AUTOSAR XML (schema 00046)
package /ComponentTypes
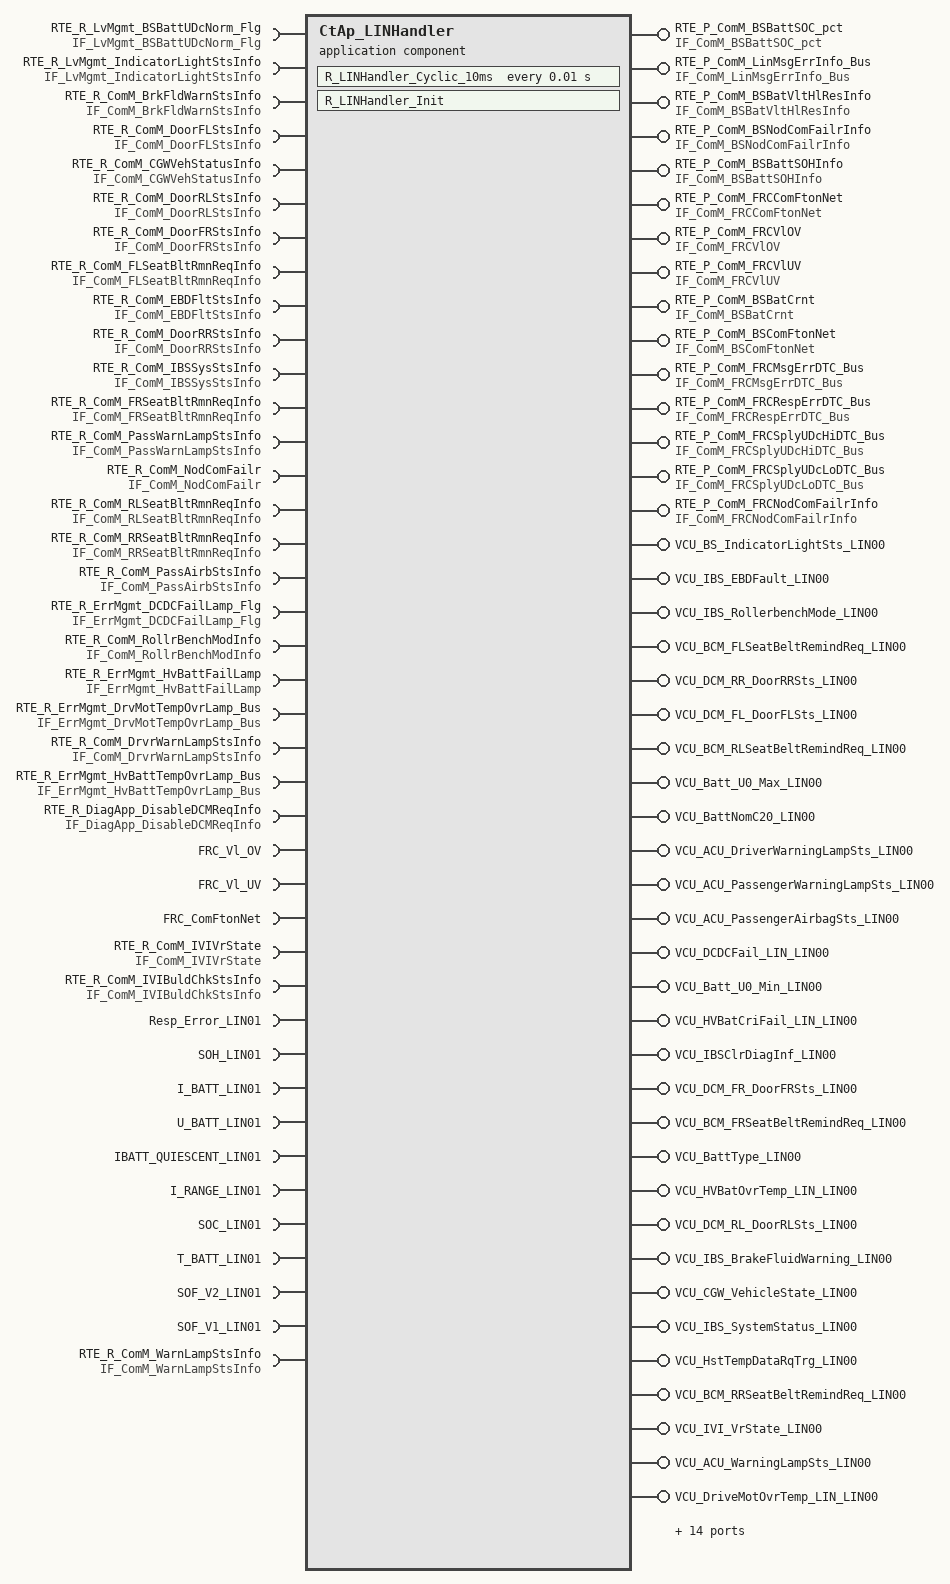
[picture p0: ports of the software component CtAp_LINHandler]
  application sw component type CtAp_LINHandler
    provide port RTE_P_ComM_BSBattSOC_pct: nonqueued-sender-com-spec{data-element=tec_ComM_BSBattSOC_pct, init-value=0}, provided-interface=IF_ComM_BSBattSOC_pct
    require port RTE_R_LvMgmt_BSBattUDcNorm_Flg: nonqueued-receiver-com-spec{data-element=tec_LvMgmt_BSBattUDcNorm_Flg, filter=data-filter-type=ALWAYS, init-value=0}, required-interface=IF_LvMgmt_BSBattUDcNorm_Flg
    4 x provide port:
      RTE_P_ComM_LinMsgErrInfo_Bus: nonqueued-sender-com-spec{data-element=tec_ComM_LinMsgErrInfo_Bus, init-value=fields=[ComM_MonStatLinMsgTimeoutDTCInfo:0, ComM_MonResLinMsgTimeoutDTCInfo:0, ComM_ErrStatLinMsgTimeoutDTCInfo:0, ComM_ErrRestatLinMsgTimeoutDTCInfo:0]}, provided-interface=IF_ComM_LinMsgErrInfo_Bus
      RTE_P_ComM_BSBatVltHlResInfo: nonqueued-sender-com-spec{data-element=tec_ComM_BSBatVltHlResInfo, init-value=0}, provided-interface=IF_ComM_BSBatVltHlResInfo
      RTE_P_ComM_BSNodComFailrInfo: nonqueued-sender-com-spec{data-element=tec_ComM_BSNodComFailrInfo, init-value=0}, provided-interface=IF_ComM_BSNodComFailrInfo
      RTE_P_ComM_BSBattSOHInfo: nonqueued-sender-com-spec{data-element=tec_ComM_BSBattSOHInfo, init-value=0}, provided-interface=IF_ComM_BSBattSOHInfo
    26 x require port:
      RTE_R_LvMgmt_IndicatorLightStsInfo: nonqueued-receiver-com-spec{data-element=tec_LvMgmt_IndicatorLightStsInfo, filter=data-filter-type=ALWAYS, init-value=0}, required-interface=IF_LvMgmt_IndicatorLightStsInfo
      RTE_R_ComM_BrkFldWarnStsInfo: nonqueued-receiver-com-spec{data-element=tec_ComM_BrkFldWarnStsInfo, filter=data-filter-type=ALWAYS, init-value=0}, required-interface=IF_ComM_BrkFldWarnStsInfo
      RTE_R_ComM_DoorFLStsInfo: nonqueued-receiver-com-spec{data-element=tec_ComM_DoorFLStsInfo, filter=data-filter-type=ALWAYS, init-value=0}, required-interface=IF_ComM_DoorFLStsInfo
      RTE_R_ComM_CGWVehStatusInfo: nonqueued-receiver-com-spec{data-element=tec_ComM_CGWVehStatusInfo, filter=data-filter-type=ALWAYS, init-value=0}, required-interface=IF_ComM_CGWVehStatusInfo
      RTE_R_ComM_DoorRLStsInfo: nonqueued-receiver-com-spec{data-element=tec_ComM_DoorRLStsInfo, filter=data-filter-type=ALWAYS, init-value=0}, required-interface=IF_ComM_DoorRLStsInfo
      RTE_R_ComM_DoorFRStsInfo: nonqueued-receiver-com-spec{data-element=tec_ComM_DoorFRStsInfo, filter=data-filter-type=ALWAYS, init-value=0}, required-interface=IF_ComM_DoorFRStsInfo
      RTE_R_ComM_FLSeatBltRmnReqInfo: nonqueued-receiver-com-spec{data-element=tec_ComM_FLSeatBltRmnReqInfo, filter=data-filter-type=ALWAYS, init-value=0}, required-interface=IF_ComM_FLSeatBltRmnReqInfo
      RTE_R_ComM_EBDFltStsInfo: nonqueued-receiver-com-spec{data-element=tec_ComM_EBDFltStsInfo, filter=data-filter-type=ALWAYS, init-value=0}, required-interface=IF_ComM_EBDFltStsInfo
      RTE_R_ComM_DoorRRStsInfo: nonqueued-receiver-com-spec{data-element=tec_ComM_DoorRRStsInfo, filter=data-filter-type=ALWAYS, init-value=0}, required-interface=IF_ComM_DoorRRStsInfo
      RTE_R_ComM_IBSSysStsInfo: nonqueued-receiver-com-spec{data-element=tec_ComM_IBSSysStsInfo, filter=data-filter-type=ALWAYS, init-value=0}, required-interface=IF_ComM_IBSSysStsInfo
      RTE_R_ComM_FRSeatBltRmnReqInfo: nonqueued-receiver-com-spec{data-element=tec_ComM_FRSeatBltRmnReqInfo, filter=data-filter-type=ALWAYS, init-value=0}, required-interface=IF_ComM_FRSeatBltRmnReqInfo
      RTE_R_ComM_PassWarnLampStsInfo: nonqueued-receiver-com-spec{data-element=tec_ComM_PassWarnLampStsInfo, filter=data-filter-type=ALWAYS, init-value=0}, required-interface=IF_ComM_PassWarnLampStsInfo
      RTE_R_ComM_NodComFailr: required-interface=IF_ComM_NodComFailr
        required-com-specs:
          data-element=tec_ComM_APTCNodComFailr_Flg, filter=data-filter-type=ALWAYS, init-value=0
          data-element=tec_ComM_ADCUNodComFailr_Flg, filter=data-filter-type=ALWAYS, init-value=0
          data-element=tec_ComM_ACUNodComFailr_Flg, filter=data-filter-type=ALWAYS, init-value=0
          data-element=tec_ComM_SGWNodComFailr_Flg, filter=data-filter-type=ALWAYS, init-value=0
          data-element=tec_ComM_CGWNodComFailr_Flg, filter=data-filter-type=ALWAYS, init-value=0
          data-element=tec_ComM_TCUNodComFailr_Flg, filter=data-filter-type=ALWAYS, init-value=0
          data-element=tec_ComM_BCMNodComFailr_Flg, filter=data-filter-type=ALWAYS, init-value=0
          data-element=tec_ComM_PRNDNodComFailr_Flg, filter=data-filter-type=ALWAYS, init-value=0
          data-element=tec_ComM_IVINodComFailr_Flg, filter=data-filter-type=ALWAYS, init-value=0
          data-element=tec_ComM_DCDCNodComFailr_Flg, filter=data-filter-type=ALWAYS, init-value=0
          data-element=tec_ComM_OBCNodComFailr_Flg, filter=data-filter-type=ALWAYS, init-value=0
          data-element=tec_ComM_CHIBSNodComFailr_Flg, filter=data-filter-type=ALWAYS, init-value=0
          data-element=tec_ComM_MCUNodComFailr_Flg, filter=data-filter-type=ALWAYS, init-value=0
          data-element=tec_ComM_EVCOMNodComFailr_Flg, filter=data-filter-type=ALWAYS, init-value=0
          data-element=tec_ComM_EPTIBSNodComFailr_Flg, filter=data-filter-type=ALWAYS, init-value=0
          data-element=tec_ComM_DCMNodComFailr_Flg, filter=data-filter-type=ALWAYS, init-value=0
          data-element=tec_ComM_BMSNodComFailr_Flg, filter=data-filter-type=ALWAYS, init-value=0
          data-element=tec_ComM_DCMRRNodComFailr_Flg, filter=data-filter-type=ALWAYS, init-value=0
          data-element=tec_ComM_DCMRLNodComFailr_Flg, filter=data-filter-type=ALWAYS, init-value=0
          data-element=tec_ComM_DCMFRNodComFailr_Flg, filter=data-filter-type=ALWAYS, init-value=0
          data-element=tec_ComM_DCMFLNodComFailr_Flg, filter=data-filter-type=ALWAYS, init-value=0
          data-element=tec_ComM_SGWCHNodComFailr_Flg, filter=data-filter-type=ALWAYS, init-value=0
      RTE_R_ComM_RLSeatBltRmnReqInfo: nonqueued-receiver-com-spec{data-element=tec_ComM_RLSeatBltRmnReqInfo, filter=data-filter-type=ALWAYS, init-value=0}, required-interface=IF_ComM_RLSeatBltRmnReqInfo
      RTE_R_ComM_RRSeatBltRmnReqInfo: nonqueued-receiver-com-spec{data-element=tec_ComM_RRSeatBltRmnReqInfo, filter=data-filter-type=ALWAYS, init-value=0}, required-interface=IF_ComM_RRSeatBltRmnReqInfo
      RTE_R_ComM_PassAirbStsInfo: nonqueued-receiver-com-spec{data-element=tec_ComM_PassAirbStsInfo, filter=data-filter-type=ALWAYS, init-value=0}, required-interface=IF_ComM_PassAirbStsInfo
      RTE_R_ErrMgmt_DCDCFailLamp_Flg: nonqueued-receiver-com-spec{data-element=tec_ErrMgmt_DCDCFailLamp_Flg, filter=data-filter-type=ALWAYS, init-value=0}, required-interface=IF_ErrMgmt_DCDCFailLamp_Flg
      RTE_R_ComM_RollrBenchModInfo: nonqueued-receiver-com-spec{data-element=tec_ComM_RollrBenchModInfo, filter=data-filter-type=ALWAYS, init-value=0}, required-interface=IF_ComM_RollrBenchModInfo
      RTE_R_ErrMgmt_HvBattFailLamp: nonqueued-receiver-com-spec{data-element=tec_ErrMgmt_HvBattFailLamp, filter=data-filter-type=ALWAYS, init-value=0}, required-interface=IF_ErrMgmt_HvBattFailLamp
      RTE_R_ErrMgmt_DrvMotTempOvrLamp_Bus: nonqueued-receiver-com-spec{data-element=tec_ErrMgmt_DrvMotTempOvrLamp_Bus, filter=data-filter-type=ALWAYS, init-value=fields=[ErrMgmt_MonStatMCUTempOvr:0, ErrMgmt_MonResMCUTempOvr:0, ErrMgmt_ErrStatMCUTempOvr:0, ErrMgmt_ErrResMCUTempOvr:0]}, required-interface=IF_ErrMgmt_DrvMotTempOvrLamp_Bus
      RTE_R_ComM_DrvrWarnLampStsInfo: nonqueued-receiver-com-spec{data-element=tec_ComM_DrvrWarnLampStsInfo, filter=data-filter-type=ALWAYS, init-value=0}, required-interface=IF_ComM_DrvrWarnLampStsInfo
      RTE_R_ErrMgmt_HvBattTempOvrLamp_Bus: nonqueued-receiver-com-spec{data-element=tec_ErrMgmt_HvBattTempOvrLamp_Bus, filter=data-filter-type=ALWAYS, init-value=fields=[ErrMgmt_MonStatBMSTempOvr:0, ErrMgmt_MonResBMSTempOvr:0, ErrMgmt_ErrStatBMSTempOvr:0, ErrMgmt_ErrResBMSTempOvr:0]}, required-interface=IF_ErrMgmt_HvBattTempOvrLamp_Bus
      RTE_R_DiagApp_DisableDCMReqInfo: nonqueued-receiver-com-spec{data-element=tec_DiagApp_DisableDCMReqInfo, filter=data-filter-type=ALWAYS, init-value=0}, required-interface=IF_DiagApp_DisableDCMReqInfo
      FRC_Vl_OV: nonqueued-receiver-com-spec{data-element=FRC_Vl_OV, init-value=1}, required-interface=FRC_Vl_OV
      FRC_Vl_UV: nonqueued-receiver-com-spec{data-element=FRC_Vl_UV, init-value=1}, required-interface=FRC_Vl_UV
      FRC_ComFtonNet: nonqueued-receiver-com-spec{data-element=FRC_ComFtonNet, enable-update=true, init-value=1}, required-interface=FRC_ComFtonNet
    5 x provide port:
      RTE_P_ComM_FRCComFtonNet: nonqueued-sender-com-spec{data-element=tec_ComM_FRCComFtonNet, init-value=0}, provided-interface=IF_ComM_FRCComFtonNet
      RTE_P_ComM_FRCVlOV: nonqueued-sender-com-spec{data-element=tec_ComM_FRCVlOV, init-value=0}, provided-interface=IF_ComM_FRCVlOV
      RTE_P_ComM_FRCVlUV: nonqueued-sender-com-spec{data-element=tec_ComM_FRCVlUV, init-value=0}, provided-interface=IF_ComM_FRCVlUV
      RTE_P_ComM_BSBatCrnt: nonqueued-sender-com-spec{data-element=tec_ComM_BSBatCrnt, init-value=0}, provided-interface=IF_ComM_BSBatCrnt
      RTE_P_ComM_BSComFtonNet: nonqueued-sender-com-spec{data-element=tec_ComM_BSComFtonNet, init-value=0}, provided-interface=IF_ComM_BSComFtonNet
    require port RTE_R_ComM_IVIVrState: nonqueued-receiver-com-spec{data-element=tec_ComM_IVIVrState, filter=data-filter-type=ALWAYS, init-value=0}, required-interface=IF_ComM_IVIVrState
    34 x provide port:
      RTE_P_ComM_FRCMsgErrDTC_Bus: nonqueued-sender-com-spec=tec_ComM_FRCMsgErrDTC_Bus, provided-interface=IF_ComM_FRCMsgErrDTC_Bus
      RTE_P_ComM_FRCRespErrDTC_Bus: nonqueued-sender-com-spec{data-element=tec_ComM_FRCRespErrDTC_Bus, init-value=fields=[ComM_MonStatLinFRCRespErrDTC:0, ComM_MonResLinFRCRespErrDTC:0, ComM_ErrStatFRCRespErrDTC:0, ComM_ErrResFRCRespErrDTC:0]}, provided-interface=IF_ComM_FRCRespErrDTC_Bus
      RTE_P_ComM_FRCSplyUDcHiDTC_Bus: nonqueued-sender-com-spec{data-element=tec_ComM_FRCSplyUDcHiDTC_Bus, init-value=fields=[ComM_MonStatFRCSplyUDcHiDTC:0, ComM_MonResFRCSplyUDcHiDTC:0, ComM_ErrStatFRCSplyUDcHiDTC:0, ComM_ErrResFRCSplyUDcHiDTC:0]}, provided-interface=IF_ComM_FRCSplyUDcHiDTC_Bus
      RTE_P_ComM_FRCSplyUDcLoDTC_Bus: nonqueued-sender-com-spec{data-element=tec_ComM_FRCSplyUDcLoDTC_Bus, init-value=fields=[ComM_MonStatFRCSplyUDcLoDTC:0, ComM_MonResFRCSplyUDcLoDTC:0, ComM_ErrStatFRCSplyUDcLoDTC:0, ComM_ErrResFRCSplyUDcLoDTC:0]}, provided-interface=IF_ComM_FRCSplyUDcLoDTC_Bus
      RTE_P_ComM_FRCNodComFailrInfo: nonqueued-sender-com-spec{data-element=tec_ComM_FRCNodComFailrInfo, init-value=0}, provided-interface=IF_ComM_FRCNodComFailrInfo
      VCU_BS_IndicatorLightSts_LIN00: nonqueued-sender-com-spec{data-element=VCU_BS_IndicatorLightSts_LIN, init-value=0}, provided-interface=VCU_BS_IndicatorLightSts_LIN00
      VCU_IBS_EBDFault_LIN00: nonqueued-sender-com-spec{data-element=VCU_IBS_EBDFault_LIN, init-value=0}, provided-interface=VCU_IBS_EBDFault_LIN00
      VCU_IBS_RollerbenchMode_LIN00: nonqueued-sender-com-spec{data-element=VCU_IBS_RollerbenchMode_LIN, init-value=0}, provided-interface=VCU_IBS_RollerbenchMode_LIN00
      VCU_BCM_FLSeatBeltRemindReq_LIN00: nonqueued-sender-com-spec{data-element=VCU_BCM_FLSeatBeltRemindReq_LIN, init-value=0}, provided-interface=VCU_BCM_FLSeatBeltRemindReq_LIN00
      VCU_DCM_RR_DoorRRSts_LIN00: nonqueued-sender-com-spec{data-element=VCU_DCM_RR_DoorRRSts_LIN, init-value=0}, provided-interface=VCU_DCM_RR_DoorRRSts_LIN00
      VCU_DCM_FL_DoorFLSts_LIN00: nonqueued-sender-com-spec{data-element=VCU_DCM_FL_DoorFLSts_LIN, init-value=0}, provided-interface=VCU_DCM_FL_DoorFLSts_LIN00
      VCU_BCM_RLSeatBeltRemindReq_LIN00: nonqueued-sender-com-spec{data-element=VCU_BCM_RLSeatBeltRemindReq_LIN, init-value=0}, provided-interface=VCU_BCM_RLSeatBeltRemindReq_LIN00
      VCU_Batt_U0_Max_LIN00: nonqueued-sender-com-spec{data-element=VCU_Batt_U0_Max_LIN, init-value=2}, provided-interface=VCU_Batt_U0_Max_LIN00
      VCU_BattNomC20_LIN00: nonqueued-sender-com-spec{data-element=VCU_BattNomC20_LIN, init-value=70}, provided-interface=VCU_BattNomC20_LIN00
      VCU_ACU_DriverWarningLampSts_LIN00: nonqueued-sender-com-spec{data-element=VCU_ACU_DriverWarningLampSts_LIN, init-value=0}, provided-interface=VCU_ACU_DriverWarningLampSts_LIN00
      VCU_ACU_PassengerWarningLampSts_LIN00: nonqueued-sender-com-spec{data-element=VCU_ACU_PassengerWarningLampSts_LIN, init-value=0}, provided-interface=VCU_ACU_PassengerWarningLampSts_LIN00
      VCU_ACU_PassengerAirbagSts_LIN00: nonqueued-sender-com-spec{data-element=VCU_ACU_PassengerAirbagSts_LIN, init-value=0}, provided-interface=VCU_ACU_PassengerAirbagSts_LIN00
      VCU_DCDCFail_LIN_LIN00: nonqueued-sender-com-spec{data-element=VCU_DCDCFail_LIN_LIN, init-value=0}, provided-interface=VCU_DCDCFail_LIN_LIN00
      VCU_Batt_U0_Min_LIN00: nonqueued-sender-com-spec{data-element=VCU_Batt_U0_Min_LIN, init-value=2}, provided-interface=VCU_Batt_U0_Min_LIN00
      VCU_HVBatCriFail_LIN_LIN00: nonqueued-sender-com-spec{data-element=VCU_HVBatCriFail_LIN_LIN, init-value=0}, provided-interface=VCU_HVBatCriFail_LIN_LIN00
      VCU_IBSClrDiagInf_LIN00: nonqueued-sender-com-spec{data-element=VCU_IBSClrDiagInf_LIN, init-value=0}, provided-interface=VCU_IBSClrDiagInf_LIN00
      VCU_DCM_FR_DoorFRSts_LIN00: nonqueued-sender-com-spec{data-element=VCU_DCM_FR_DoorFRSts_LIN, init-value=0}, provided-interface=VCU_DCM_FR_DoorFRSts_LIN00
      VCU_BCM_FRSeatBeltRemindReq_LIN00: nonqueued-sender-com-spec{data-element=VCU_BCM_FRSeatBeltRemindReq_LIN, init-value=0}, provided-interface=VCU_BCM_FRSeatBeltRemindReq_LIN00
      VCU_BattType_LIN00: nonqueued-sender-com-spec{data-element=VCU_BattType_LIN, init-value=0}, provided-interface=VCU_BattType_LIN00
      VCU_HVBatOvrTemp_LIN_LIN00: nonqueued-sender-com-spec{data-element=VCU_HVBatOvrTemp_LIN_LIN, init-value=0}, provided-interface=VCU_HVBatOvrTemp_LIN_LIN00
      VCU_DCM_RL_DoorRLSts_LIN00: nonqueued-sender-com-spec{data-element=VCU_DCM_RL_DoorRLSts_LIN, init-value=0}, provided-interface=VCU_DCM_RL_DoorRLSts_LIN00
      VCU_IBS_BrakeFluidWarning_LIN00: nonqueued-sender-com-spec{data-element=VCU_IBS_BrakeFluidWarning_LIN, init-value=0}, provided-interface=VCU_IBS_BrakeFluidWarning_LIN00
      VCU_CGW_VehicleState_LIN00: nonqueued-sender-com-spec{data-element=VCU_CGW_VehicleState_LIN, init-value=0}, provided-interface=VCU_CGW_VehicleState_LIN00
      VCU_IBS_SystemStatus_LIN00: nonqueued-sender-com-spec{data-element=VCU_IBS_SystemStatus_LIN, init-value=0}, provided-interface=VCU_IBS_SystemStatus_LIN00
      VCU_HstTempDataRqTrg_LIN00: nonqueued-sender-com-spec{data-element=VCU_HstTempDataRqTrg_LIN, init-value=0}, provided-interface=VCU_HstTempDataRqTrg_LIN00
      VCU_BCM_RRSeatBeltRemindReq_LIN00: nonqueued-sender-com-spec{data-element=VCU_BCM_RRSeatBeltRemindReq_LIN, init-value=0}, provided-interface=VCU_BCM_RRSeatBeltRemindReq_LIN00
      VCU_IVI_VrState_LIN00: nonqueued-sender-com-spec{data-element=VCU_IVI_VrState_LIN, init-value=0}, provided-interface=VCU_IVI_VrState_LIN00
      VCU_ACU_WarningLampSts_LIN00: nonqueued-sender-com-spec{data-element=VCU_ACU_WarningLampSts_LIN, init-value=0}, provided-interface=VCU_ACU_WarningLampSts_LIN00
      VCU_DriveMotOvrTemp_LIN_LIN00: nonqueued-sender-com-spec{data-element=VCU_DriveMotOvrTemp_LIN_LIN, init-value=0}, provided-interface=VCU_DriveMotOvrTemp_LIN_LIN00
    require port RTE_R_ComM_IVIBuldChkStsInfo: nonqueued-receiver-com-spec{data-element=tec_ComM_IVIBuldChkStsInfo, filter=data-filter-type=ALWAYS, init-value=0}, required-interface=IF_ComM_IVIBuldChkStsInfo
    provide port VCU_IVI_BulbCheckStsLIN01: nonqueued-sender-com-spec{data-element=VCU_IVI_BulbCheckStsLIN01, init-value=0}, provided-interface=VCU_IVI_BulbCheckStsLIN01
    provide port RTE_P_ComM_BSHCrnt: nonqueued-sender-com-spec{data-element=tec_ComM_BSHCrnt, init-value=0}, provided-interface=IF_ComM_BSHCrnt
    provide port RTE_P_ComM_BSQuiescentCurrent: nonqueued-sender-com-spec{data-element=tec_ComM_BSQuiescentCurrent, init-value=0}, provided-interface=IF_ComM_BSQuiescentCurrent
    require port Resp_Error_LIN01: nonqueued-receiver-com-spec{data-element=Resp_Error_LIN01, enable-update=true, init-value=0}, required-interface=Resp_Error_LIN01
    provide port RTE_P_ComM_BSBattIDcInfo: nonqueued-sender-com-spec{data-element=tec_ComM_BSBattIDcInfo, init-value=0}, provided-interface=IF_ComM_BSBattIDcInfo
    provide port RTE_P_ComM_BSBattTempInfo: nonqueued-sender-com-spec=tec_ComM_BSBattTempInfo, provided-interface=IF_ComM_BSBattTempInfo
    7 x require port:
      SOH_LIN01: nonqueued-receiver-com-spec{data-element=SOH_LIN01, init-value=255}, required-interface=SOH_LIN01
      I_BATT_LIN01: nonqueued-receiver-com-spec{data-element=I_BATT_LIN01, init-value=65535}, required-interface=I_BATT_LIN01
      U_BATT_LIN01: nonqueued-receiver-com-spec{data-element=U_BATT_LIN01, init-value=16383}, required-interface=U_BATT_LIN01
      IBATT_QUIESCENT_LIN01: nonqueued-receiver-com-spec{data-element=IBATT_QUIESCENT_LIN01, init-value=255}, required-interface=IBATT_QUIESCENT_LIN01
      I_RANGE_LIN01: nonqueued-receiver-com-spec{data-element=I_RANGE_LIN01, init-value=3}, required-interface=I_RANGE_LIN01
      SOC_LIN01: nonqueued-receiver-com-spec{data-element=SOC_LIN01, init-value=1}, required-interface=SOC_LIN01
      T_BATT_LIN01: nonqueued-receiver-com-spec{data-element=T_BATT_LIN01, init-value=255}, required-interface=T_BATT_LIN01
    7 x provide port:
      ChargeCurrWU_Ena_LIN01: nonqueued-sender-com-spec{data-element=ChargeCurrWU_Ena_LIN01, init-value=1}, provided-interface=ChargeCurrWU_Ena_LIN01
      SOCWU_Ena_LIN01: nonqueued-sender-com-spec{data-element=SOCWU_Ena_LIN01, init-value=1}, provided-interface=SOCWU_Ena_LIN01
      DisChargeCurrWU_Treshold_LIN01: nonqueued-sender-com-spec{data-element=DisChargeCurrWU_Treshold_LIN01, init-value=145}, provided-interface=DisChargeCurrWU_Treshold_LIN01
      SOCWU_Treshold_LIN01: nonqueued-sender-com-spec{data-element=SOCWU_Treshold_LIN01, init-value=70}, provided-interface=SOCWU_Treshold_LIN01
      DisChargeCurrWU_Ena_LIN01: nonqueued-sender-com-spec{data-element=DisChargeCurrWU_Ena_LIN01, init-value=1}, provided-interface=DisChargeCurrWU_Ena_LIN01
      ChargeCurrWU_Treshold_LIN01: nonqueued-sender-com-spec{data-element=ChargeCurrWU_Treshold_LIN01, init-value=30}, provided-interface=ChargeCurrWU_Treshold_LIN01
      RTE_P_ComM_BS01_IsUpdated: nonqueued-sender-com-spec{data-element=tec_ComM_BS01_IsUpdated, init-value=0}, provided-interface=IF_ComM_BS01_IsUpdated
    require port SOF_V2_LIN01: nonqueued-receiver-com-spec{data-element=SOF_V2_LIN01, init-value=255}, required-interface=SOF_V2_LIN01
    require port SOF_V1_LIN01: nonqueued-receiver-com-spec{data-element=SOF_V1_LIN01, init-value=255}, required-interface=SOF_V1_LIN01
    provide port RTE_P_ComM_BSSOFV1Info: nonqueued-sender-com-spec{data-element=tec_ComM_BSSOFV1Info, init-value=0}, provided-interface=IF_ComM_BSSOFV1Info
    provide port RTE_P_ComM_BSSOFV2Info: nonqueued-sender-com-spec{data-element=tec_ComM_BSSOFV2Info, init-value=0}, provided-interface=IF_ComM_BSSOFV2Info
    require port RTE_R_ComM_WarnLampStsInfo: nonqueued-receiver-com-spec{data-element=tec_ComM_WarnLampStsInfo, filter=data-filter-type=ALWAYS, init-value=0}, required-interface=IF_ComM_WarnLampStsInfo
    behavior CtAp_LINHandler_InternalBehavior
      timing event TMT_R_LINHandler_Cyclic_10ms: start-on-event=R_LINHandler_Cyclic_10ms, period=0.01
      init event CtAp_LinHandler_InitEvent: start-on-event=R_LINHandler_Init
      runnable R_LINHandler_Cyclic_10ms
        data-receive-point-by-arguments:
          48 x access:
            REC_FRC_ComFtonNet_FRC_ComFtonNet: accessed-variable=FRC_ComFtonNet.FRC_ComFtonNet
            REC_FRC_Vl_OV_FRC_Vl_OV: accessed-variable=FRC_Vl_OV.FRC_Vl_OV
            REC_FRC_Vl_UV_FRC_Vl_UV: accessed-variable=FRC_Vl_UV.FRC_Vl_UV
            REC_RTE_R_ComM_BrkFldWarnStsInfo_tec_ComM_BrkFldWarnStsInfo: accessed-variable=RTE_R_ComM_BrkFldWarnStsInfo.tec_ComM_BrkFldWarnStsInfo
            REC_RTE_R_ComM_CGWVehStatusInfo_tec_ComM_CGWVehStatusInfo: accessed-variable=RTE_R_ComM_CGWVehStatusInfo.tec_ComM_CGWVehStatusInfo
            REC_RTE_R_ComM_DoorFLStsInfo_tec_ComM_DoorFLStsInfo: accessed-variable=RTE_R_ComM_DoorFLStsInfo.tec_ComM_DoorFLStsInfo
            REC_RTE_R_ComM_DoorFRStsInfo_tec_ComM_DoorFRStsInfo: accessed-variable=RTE_R_ComM_DoorFRStsInfo.tec_ComM_DoorFRStsInfo
            REC_RTE_R_ComM_DoorRLStsInfo_tec_ComM_DoorRLStsInfo: accessed-variable=RTE_R_ComM_DoorRLStsInfo.tec_ComM_DoorRLStsInfo
            REC_RTE_R_ComM_DoorRRStsInfo_tec_ComM_DoorRRStsInfo: accessed-variable=RTE_R_ComM_DoorRRStsInfo.tec_ComM_DoorRRStsInfo
            REC_RTE_R_ComM_DrvrWarnLampStsInfo_tec_ComM_DrvrWarnLampStsInfo: accessed-variable=RTE_R_ComM_DrvrWarnLampStsInfo.tec_ComM_DrvrWarnLampStsInfo
            REC_RTE_R_ComM_EBDFltStsInfo_tec_ComM_EBDFltStsInfo: accessed-variable=RTE_R_ComM_EBDFltStsInfo.tec_ComM_EBDFltStsInfo
            REC_RTE_R_ComM_FLSeatBltRmnReqInfo_tec_ComM_FLSeatBltRmnReqInfo: accessed-variable=RTE_R_ComM_FLSeatBltRmnReqInfo.tec_ComM_FLSeatBltRmnReqInfo
            REC_RTE_R_ComM_FRSeatBltRmnReqInfo_tec_ComM_FRSeatBltRmnReqInfo: accessed-variable=RTE_R_ComM_FRSeatBltRmnReqInfo.tec_ComM_FRSeatBltRmnReqInfo
            REC_RTE_R_ComM_IBSSysStsInfo_tec_ComM_IBSSysStsInfo: accessed-variable=RTE_R_ComM_IBSSysStsInfo.tec_ComM_IBSSysStsInfo
            REC_RTE_R_ComM_IVIVrState_tec_ComM_IVIVrState: accessed-variable=RTE_R_ComM_IVIVrState.tec_ComM_IVIVrState
            REC_RTE_R_ComM_NodComFailr_tec_ComM_ACUNodComFailr_Flg: accessed-variable=RTE_R_ComM_NodComFailr.tec_ComM_ACUNodComFailr_Flg
            REC_RTE_R_ComM_NodComFailr_tec_ComM_BCMNodComFailr_Flg: accessed-variable=RTE_R_ComM_NodComFailr.tec_ComM_BCMNodComFailr_Flg
            REC_RTE_R_ComM_NodComFailr_tec_ComM_CGWNodComFailr_Flg: accessed-variable=RTE_R_ComM_NodComFailr.tec_ComM_CGWNodComFailr_Flg
            REC_RTE_R_ComM_NodComFailr_tec_ComM_CHIBSNodComFailr_Flg: accessed-variable=RTE_R_ComM_NodComFailr.tec_ComM_CHIBSNodComFailr_Flg
            REC_RTE_R_ComM_NodComFailr_tec_ComM_DCMFLNodComFailr_Flg: accessed-variable=RTE_R_ComM_NodComFailr.tec_ComM_DCMFLNodComFailr_Flg
            REC_RTE_R_ComM_NodComFailr_tec_ComM_DCMFRNodComFailr_Flg: accessed-variable=RTE_R_ComM_NodComFailr.tec_ComM_DCMFRNodComFailr_Flg
            REC_RTE_R_ComM_NodComFailr_tec_ComM_DCMRLNodComFailr_Flg: accessed-variable=RTE_R_ComM_NodComFailr.tec_ComM_DCMRLNodComFailr_Flg
            REC_RTE_R_ComM_NodComFailr_tec_ComM_DCMRRNodComFailr_Flg: accessed-variable=RTE_R_ComM_NodComFailr.tec_ComM_DCMRRNodComFailr_Flg
            REC_RTE_R_ComM_NodComFailr_tec_ComM_IVINodComFailr_Flg: accessed-variable=RTE_R_ComM_NodComFailr.tec_ComM_IVINodComFailr_Flg
            REC_RTE_R_ComM_PassAirbStsInfo_tec_ComM_PassAirbStsInfo: accessed-variable=RTE_R_ComM_PassAirbStsInfo.tec_ComM_PassAirbStsInfo
            REC_RTE_R_ComM_PassWarnLampStsInfo_tec_ComM_PassWarnLampStsInfo: accessed-variable=RTE_R_ComM_PassWarnLampStsInfo.tec_ComM_PassWarnLampStsInfo
            REC_RTE_R_ComM_RLSeatBltRmnReqInfo_tec_ComM_RLSeatBltRmnReqInfo: accessed-variable=RTE_R_ComM_RLSeatBltRmnReqInfo.tec_ComM_RLSeatBltRmnReqInfo
            REC_RTE_R_ComM_RRSeatBltRmnReqInfo_tec_ComM_RRSeatBltRmnReqInfo: accessed-variable=RTE_R_ComM_RRSeatBltRmnReqInfo.tec_ComM_RRSeatBltRmnReqInfo
            REC_RTE_R_ComM_RollrBenchModInfo_tec_ComM_RollrBenchModInfo: accessed-variable=RTE_R_ComM_RollrBenchModInfo.tec_ComM_RollrBenchModInfo
            REC_RTE_R_DiagApp_DisableDCMReqInfo_tec_DiagApp_DisableDCMReqInfo: accessed-variable=RTE_R_DiagApp_DisableDCMReqInfo.tec_DiagApp_DisableDCMReqInfo
            REC_RTE_R_ErrMgmt_DCDCFailLamp_Flg_tec_ErrMgmt_DCDCFailLamp_Flg: accessed-variable=RTE_R_ErrMgmt_DCDCFailLamp_Flg.tec_ErrMgmt_DCDCFailLamp_Flg
            REC_RTE_R_ErrMgmt_DrvMotTempOvrLamp_Bus_tec_ErrMgmt_DrvMotTempOvrLamp_Bus: accessed-variable=RTE_R_ErrMgmt_DrvMotTempOvrLamp_Bus.tec_ErrMgmt_DrvMotTempOvrLamp_Bus
            REC_RTE_R_ErrMgmt_HvBattFailLamp_tec_ErrMgmt_HvBattFailLamp: accessed-variable=RTE_R_ErrMgmt_HvBattFailLamp.tec_ErrMgmt_HvBattFailLamp
            REC_RTE_R_ErrMgmt_HvBattTempOvrLamp_Bus_tec_ErrMgmt_HvBattTempOvrLamp_Bus: accessed-variable=RTE_R_ErrMgmt_HvBattTempOvrLamp_Bus.tec_ErrMgmt_HvBattTempOvrLamp_Bus
            REC_RTE_R_LvMgmt_BSBattUDcNorm_Flg_tec_LvMgmt_BSBattUDcNorm_Flg: accessed-variable=RTE_R_LvMgmt_BSBattUDcNorm_Flg.tec_LvMgmt_BSBattUDcNorm_Flg
            REC_RTE_R_LvMgmt_IndicatorLightStsInfo_tec_LvMgmt_IndicatorLightStsInfo: accessed-variable=RTE_R_LvMgmt_IndicatorLightStsInfo.tec_LvMgmt_IndicatorLightStsInfo
            REC_IBATT_QUIESCENT_LIN01_IBATT_QUIESCENT_LIN01: accessed-variable=IBATT_QUIESCENT_LIN01.IBATT_QUIESCENT_LIN01
            REC_I_BATT_LIN01_I_BATT_LIN01: accessed-variable=I_BATT_LIN01.I_BATT_LIN01
            REC_I_RANGE_LIN01_I_RANGE_LIN01: accessed-variable=I_RANGE_LIN01.I_RANGE_LIN01
            REC_RTE_R_ComM_IVIBuldChkStsInfo_tec_ComM_IVIBuldChkStsInfo: accessed-variable=RTE_R_ComM_IVIBuldChkStsInfo.tec_ComM_IVIBuldChkStsInfo
            REC_Resp_Error_LIN01_Resp_Error_LIN01: accessed-variable=Resp_Error_LIN01.Resp_Error_LIN01
            REC_SOC_LIN01_SOC_LIN01: accessed-variable=SOC_LIN01.SOC_LIN01
            REC_SOH_LIN01_SOH_LIN01: accessed-variable=SOH_LIN01.SOH_LIN01
            REC_T_BATT_LIN01_T_BATT_LIN01: accessed-variable=T_BATT_LIN01.T_BATT_LIN01
            REC_U_BATT_LIN01_U_BATT_LIN01: accessed-variable=U_BATT_LIN01.U_BATT_LIN01
            REC_SOF_V1_LIN01_SOF_V1_LIN01: accessed-variable=SOF_V1_LIN01.SOF_V1_LIN01
            REC_SOF_V2_LIN01_SOF_V2_LIN01: accessed-variable=SOF_V2_LIN01.SOF_V2_LIN01
            REC_RTE_R_ComM_WarnLampStsInfo_tec_ComM_WarnLampStsInfo: accessed-variable=RTE_R_ComM_WarnLampStsInfo.tec_ComM_WarnLampStsInfo
        data-send-points:
          58 x access:
            SEND_RTE_P_ComM_BSBatCrnt_tec_ComM_BSBatCrnt: accessed-variable=RTE_P_ComM_BSBatCrnt.tec_ComM_BSBatCrnt
            SEND_RTE_P_ComM_BSBatVltHlResInfo_tec_ComM_BSBatVltHlResInfo: accessed-variable=RTE_P_ComM_BSBatVltHlResInfo.tec_ComM_BSBatVltHlResInfo
            SEND_RTE_P_ComM_BSBattSOC_pct_tec_ComM_BSBattSOC_pct: accessed-variable=RTE_P_ComM_BSBattSOC_pct.tec_ComM_BSBattSOC_pct
            SEND_RTE_P_ComM_BSBattSOHInfo_tec_ComM_BSBattSOHInfo: accessed-variable=RTE_P_ComM_BSBattSOHInfo.tec_ComM_BSBattSOHInfo
            SEND_RTE_P_ComM_BSComFtonNet_tec_ComM_BSComFtonNe: accessed-variable=RTE_P_ComM_BSComFtonNet.tec_ComM_BSComFtonNet
            SEND_RTE_P_ComM_BSNodComFailrInfo_tec_ComM_BSNodComFailrInfo: accessed-variable=RTE_P_ComM_BSNodComFailrInfo.tec_ComM_BSNodComFailrInfo
            SEND_RTE_P_ComM_FRCComFtonNet_tec_ComM_FRCComFtonNet: accessed-variable=RTE_P_ComM_FRCComFtonNet.tec_ComM_FRCComFtonNet
            SEND_RTE_P_ComM_FRCVlOV_tec_ComM_FRCVlOV: accessed-variable=RTE_P_ComM_FRCVlOV.tec_ComM_FRCVlOV
            SEND_RTE_P_ComM_FRCVlUV_tec_ComM_FRCVlUV: accessed-variable=RTE_P_ComM_FRCVlUV.tec_ComM_FRCVlUV
            SEND_RTE_P_ComM_LinMsgErrInfo_Bus_tec_ComM_LinMsgErrInfo_Bus: accessed-variable=RTE_P_ComM_LinMsgErrInfo_Bus.tec_ComM_LinMsgErrInfo_Bus
            SEND_RTE_P_ComM_FRCMsgErrDTC_Bus_tec_ComM_FRCMsgErrDTC_Bus: accessed-variable=RTE_P_ComM_FRCMsgErrDTC_Bus.tec_ComM_FRCMsgErrDTC_Bus
            SEND_RTE_P_ComM_FRCNodComFailrInfo_tec_ComM_FRCNodComFailrInfo: accessed-variable=RTE_P_ComM_FRCNodComFailrInfo.tec_ComM_FRCNodComFailrInfo
            SEND_RTE_P_ComM_FRCRespErrDTC_Bus_tec_ComM_FRCRespErrDTC_Bus: accessed-variable=RTE_P_ComM_FRCRespErrDTC_Bus.tec_ComM_FRCRespErrDTC_Bus
            SEND_RTE_P_ComM_FRCSplyUDcHiDTC_Bus_tec_ComM_FRCSplyUDcHiDTC_Bus: accessed-variable=RTE_P_ComM_FRCSplyUDcHiDTC_Bus.tec_ComM_FRCSplyUDcHiDTC_Bus
            SEND_RTE_P_ComM_FRCSplyUDcLoDTC_Bus_tec_ComM_FRCSplyUDcLoDTC_Bus: accessed-variable=RTE_P_ComM_FRCSplyUDcLoDTC_Bus.tec_ComM_FRCSplyUDcLoDTC_Bus
            SEND_VCU_ACU_DriverWarningLampSts_LIN00_VCU_ACU_DriverWarningLampSts_LIN: accessed-variable=VCU_ACU_DriverWarningLampSts_LIN00.VCU_ACU_DriverWarningLampSts_LIN
            SEND_VCU_ACU_PassengerAirbagSts_LIN00_VCU_ACU_PassengerAirbagSts_LIN: accessed-variable=VCU_ACU_PassengerAirbagSts_LIN00.VCU_ACU_PassengerAirbagSts_LIN
            SEND_VCU_ACU_PassengerWarningLampSts_LIN00_VCU_ACU_PassengerWarningLampSts_LIN: accessed-variable=VCU_ACU_PassengerWarningLampSts_LIN00.VCU_ACU_PassengerWarningLampSts_LIN
            SEND_VCU_ACU_WarningLampSts_LIN00_VCU_ACU_WarningLampSts_LIN: accessed-variable=VCU_ACU_WarningLampSts_LIN00.VCU_ACU_WarningLampSts_LIN
            SEND_VCU_BCM_FLSeatBeltRemindReq_LIN00_VCU_BCM_FLSeatBeltRemindReq_LIN: accessed-variable=VCU_BCM_FLSeatBeltRemindReq_LIN00.VCU_BCM_FLSeatBeltRemindReq_LIN
            SEND_VCU_BCM_FRSeatBeltRemindReq_LIN00_VCU_BCM_FRSeatBeltRemindReq_LIN: accessed-variable=VCU_BCM_FRSeatBeltRemindReq_LIN00.VCU_BCM_FRSeatBeltRemindReq_LIN
            SEND_VCU_BCM_RLSeatBeltRemindReq_LIN00_VCU_BCM_RLSeatBeltRemindReq_LIN: accessed-variable=VCU_BCM_RLSeatBeltRemindReq_LIN00.VCU_BCM_RLSeatBeltRemindReq_LIN
            SEND_VCU_BCM_RRSeatBeltRemindReq_LIN00_VCU_BCM_RRSeatBeltRemindReq_LIN: accessed-variable=VCU_BCM_RRSeatBeltRemindReq_LIN00.VCU_BCM_RRSeatBeltRemindReq_LIN
            SEND_VCU_BS_IndicatorLightSts_LIN00_VCU_BS_IndicatorLightSts_LIN: accessed-variable=VCU_BS_IndicatorLightSts_LIN00.VCU_BS_IndicatorLightSts_LIN
            SEND_VCU_BattNomC20_LIN00_VCU_BattNomC20_LIN: accessed-variable=VCU_BattNomC20_LIN00.VCU_BattNomC20_LIN
            SEND_VCU_BattType_LIN00_VCU_BattType_LIN: accessed-variable=VCU_BattType_LIN00.VCU_BattType_LIN
            SEND_VCU_Batt_U0_Max_LIN00_VCU_Batt_U0_Max_LIN: accessed-variable=VCU_Batt_U0_Max_LIN00.VCU_Batt_U0_Max_LIN
            SEND_VCU_Batt_U0_Min_LIN00_VCU_Batt_U0_Min_LIN: accessed-variable=VCU_Batt_U0_Min_LIN00.VCU_Batt_U0_Min_LIN
            SEND_VCU_CGW_VehicleState_LIN00_VCU_CGW_VehicleState_LIN: accessed-variable=VCU_CGW_VehicleState_LIN00.VCU_CGW_VehicleState_LIN
            SEND_VCU_DCDCFail_LIN_LIN00_VCU_DCDCFail_LIN_LIN: accessed-variable=VCU_DCDCFail_LIN_LIN00.VCU_DCDCFail_LIN_LIN
            SEND_VCU_DCM_FL_DoorFLSts_LIN00_VCU_DCM_FL_DoorFLSts_LIN: accessed-variable=VCU_DCM_FL_DoorFLSts_LIN00.VCU_DCM_FL_DoorFLSts_LIN
            SEND_VCU_DCM_FR_DoorFRSts_LIN00_VCU_DCM_FR_DoorFRSts_LIN: accessed-variable=VCU_DCM_FR_DoorFRSts_LIN00.VCU_DCM_FR_DoorFRSts_LIN
            SEND_VCU_DCM_RL_DoorRLSts_LIN00_VCU_DCM_RL_DoorRLSts_LIN: accessed-variable=VCU_DCM_RL_DoorRLSts_LIN00.VCU_DCM_RL_DoorRLSts_LIN
            SEND_VCU_DCM_RR_DoorRRSts_LIN00_VCU_DCM_RR_DoorRRSts_LIN: accessed-variable=VCU_DCM_RR_DoorRRSts_LIN00.VCU_DCM_RR_DoorRRSts_LIN
            SEND_VCU_DriveMotOvrTemp_LIN_LIN00_VCU_DriveMotOvrTemp_LIN_LIN: accessed-variable=VCU_DriveMotOvrTemp_LIN_LIN00.VCU_DriveMotOvrTemp_LIN_LIN
            SEND_VCU_HVBatCriFail_LIN_LIN00_VCU_HVBatCriFail_LIN_LIN: accessed-variable=VCU_HVBatCriFail_LIN_LIN00.VCU_HVBatCriFail_LIN_LIN
            SEND_VCU_HVBatOvrTemp_LIN_LIN00_VCU_HVBatOvrTemp_LIN_LIN: accessed-variable=VCU_HVBatOvrTemp_LIN_LIN00.VCU_HVBatOvrTemp_LIN_LIN
            SEND_VCU_HstTempDataRqTrg_LIN00_VCU_HstTempDataRqTrg_LIN: accessed-variable=VCU_HstTempDataRqTrg_LIN00.VCU_HstTempDataRqTrg_LIN
            SEND_VCU_IBSClrDiagInf_LIN00_VCU_IBSClrDiagInf_LIN: accessed-variable=VCU_IBSClrDiagInf_LIN00.VCU_IBSClrDiagInf_LIN
            SEND_VCU_IBS_BrakeFluidWarning_LIN00_VCU_IBS_BrakeFluidWarning_LIN: accessed-variable=VCU_IBS_BrakeFluidWarning_LIN00.VCU_IBS_BrakeFluidWarning_LIN
            SEND_VCU_IBS_EBDFault_LIN00_VCU_IBS_EBDFault_LIN: accessed-variable=VCU_IBS_EBDFault_LIN00.VCU_IBS_EBDFault_LIN
            SEND_VCU_IBS_RollerbenchMode_LIN00_VCU_IBS_RollerbenchMode_LIN: accessed-variable=VCU_IBS_RollerbenchMode_LIN00.VCU_IBS_RollerbenchMode_LIN
            SEND_VCU_IBS_SystemStatus_LIN00_VCU_IBS_SystemStatus_LIN: accessed-variable=VCU_IBS_SystemStatus_LIN00.VCU_IBS_SystemStatus_LIN
            SEND_VCU_IVI_VrState_LIN00_VCU_IVI_VrState_LIN: accessed-variable=VCU_IVI_VrState_LIN00.VCU_IVI_VrState_LIN
            SEND_ChargeCurrWU_Ena_LIN01_ChargeCurrWU_Ena_LIN01: accessed-variable=ChargeCurrWU_Ena_LIN01.ChargeCurrWU_Ena_LIN01
            SEND_ChargeCurrWU_Treshold_LIN01_ChargeCurrWU_Treshold_LIN01: accessed-variable=ChargeCurrWU_Treshold_LIN01.ChargeCurrWU_Treshold_LIN01
            SEND_DisChargeCurrWU_Ena_LIN01_DisChargeCurrWU_Ena_LIN01: accessed-variable=DisChargeCurrWU_Ena_LIN01.DisChargeCurrWU_Ena_LIN01
            SEND_DisChargeCurrWU_Treshold_LIN01_DisChargeCurrWU_Treshold_LIN01: accessed-variable=DisChargeCurrWU_Treshold_LIN01.DisChargeCurrWU_Treshold_LIN01
            SEND_RTE_P_ComM_BSBattIDcInfo_tec_ComM_BSBattIDcInfo: accessed-variable=RTE_P_ComM_BSBattIDcInfo.tec_ComM_BSBattIDcInfo
            SEND_RTE_P_ComM_BSBattTempInfo_tec_ComM_BSBattTempInfo: accessed-variable=RTE_P_ComM_BSBattTempInfo.tec_ComM_BSBattTempInfo
            SEND_RTE_P_ComM_BSHCrnt_tec_ComM_BSHCrnt: accessed-variable=RTE_P_ComM_BSHCrnt.tec_ComM_BSHCrnt
            SEND_RTE_P_ComM_BSQuiescentCurrent_tec_ComM_BSQuiescentCurrent: accessed-variable=RTE_P_ComM_BSQuiescentCurrent.tec_ComM_BSQuiescentCurrent
            SEND_SOCWU_Ena_LIN01_SOCWU_Ena_LIN01: accessed-variable=SOCWU_Ena_LIN01.SOCWU_Ena_LIN01
            SEND_SOCWU_Treshold_LIN01_SOCWU_Treshold_LIN01: accessed-variable=SOCWU_Treshold_LIN01.SOCWU_Treshold_LIN01
            SEND_VCU_IVI_BulbCheckStsLIN01_VCU_IVI_BulbCheckStsLIN01: accessed-variable=VCU_IVI_BulbCheckStsLIN01.VCU_IVI_BulbCheckStsLIN01
            SEND_RTE_P_ComM_BS01_IsUpdated_tec_ComM_BS01_IsUpdated: accessed-variable=RTE_P_ComM_BS01_IsUpdated.tec_ComM_BS01_IsUpdated
            SEND_RTE_P_ComM_BSSOFV1Info_tec_ComM_BSSOFV1Info: accessed-variable=RTE_P_ComM_BSSOFV1Info.tec_ComM_BSSOFV1Info
            SEND_RTE_P_ComM_BSSOFV2Info_tec_ComM_BSSOFV2Info: accessed-variable=RTE_P_ComM_BSSOFV2Info.tec_ComM_BSSOFV2Info
      runnable R_LINHandler_Init
  swc implementation CtAp_LINHandler_Implementation: behavior=CtAp_LINHandler_InternalBehavior
